VERSION "Proposition POC une paire avant - non validee pour le bus TRAXX"

NS_ :

BS_:

BU_: TRAXX_PALPEUR TRAXX_PC

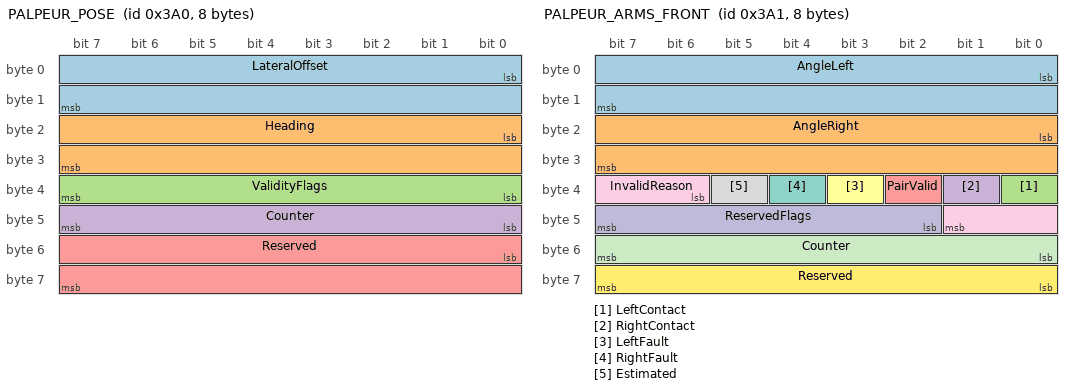
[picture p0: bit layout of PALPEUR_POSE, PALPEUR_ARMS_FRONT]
BO_ 928 PALPEUR_POSE: 8 TRAXX_PALPEUR
 SG_ LateralOffset : 0|16@1- (0.1,0) [-3276.8|3276.7] "mm" TRAXX_PC
 SG_ Heading : 16|16@1- (0.01,0) [-327.68|327.67] "deg" TRAXX_PC
 SG_ ValidityFlags : 32|8@1+ (1,0) [0|255] "" TRAXX_PC
 SG_ Counter : 40|8@1+ (1,0) [0|255] "" TRAXX_PC
 SG_ Reserved : 48|16@1+ (1,0) [0|65535] "" TRAXX_PC

BO_ 929 PALPEUR_ARMS_FRONT: 8 TRAXX_PALPEUR
 SG_ AngleLeft : 0|16@1- (0.01,0) [-327.68|327.67] "deg" TRAXX_PC
 SG_ AngleRight : 16|16@1- (0.01,0) [-327.68|327.67] "deg" TRAXX_PC
 SG_ LeftContact : 32|1@1+ (1,0) [0|1] "" TRAXX_PC
 SG_ RightContact : 33|1@1+ (1,0) [0|1] "" TRAXX_PC
 SG_ PairValid : 34|1@1+ (1,0) [0|1] "" TRAXX_PC
 SG_ LeftFault : 35|1@1+ (1,0) [0|1] "" TRAXX_PC
 SG_ RightFault : 36|1@1+ (1,0) [0|1] "" TRAXX_PC
 SG_ Estimated : 37|1@1+ (1,0) [0|1] "" TRAXX_PC
 SG_ InvalidReason : 38|4@1+ (1,0) [0|15] "" TRAXX_PC
 SG_ ReservedFlags : 42|6@1+ (1,0) [0|63] "" TRAXX_PC
 SG_ Counter : 48|8@1+ (1,0) [0|255] "" TRAXX_PC
 SG_ Reserved : 56|8@1+ (1,0) [0|255] "" TRAXX_PC

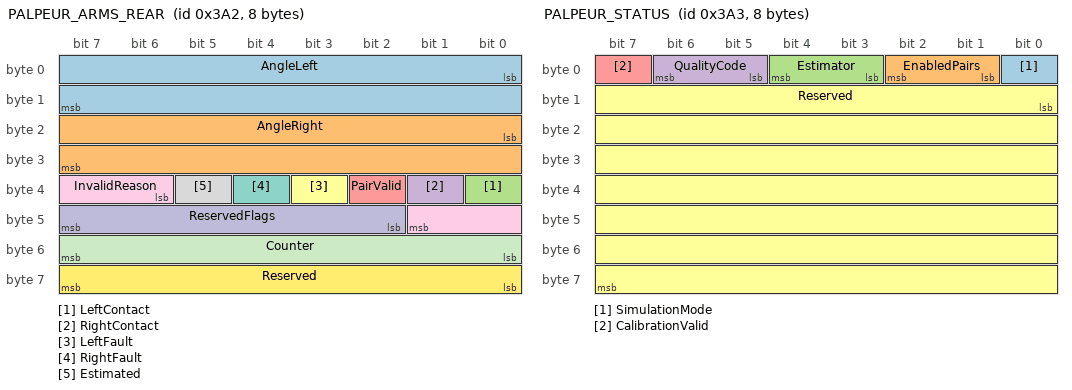
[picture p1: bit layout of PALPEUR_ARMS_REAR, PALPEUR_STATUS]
BO_ 930 PALPEUR_ARMS_REAR: 8 TRAXX_PALPEUR
 SG_ AngleLeft : 0|16@1- (0.01,0) [-327.68|327.67] "deg" TRAXX_PC
 SG_ AngleRight : 16|16@1- (0.01,0) [-327.68|327.67] "deg" TRAXX_PC
 SG_ LeftContact : 32|1@1+ (1,0) [0|1] "" TRAXX_PC
 SG_ RightContact : 33|1@1+ (1,0) [0|1] "" TRAXX_PC
 SG_ PairValid : 34|1@1+ (1,0) [0|1] "" TRAXX_PC
 SG_ LeftFault : 35|1@1+ (1,0) [0|1] "" TRAXX_PC
 SG_ RightFault : 36|1@1+ (1,0) [0|1] "" TRAXX_PC
 SG_ Estimated : 37|1@1+ (1,0) [0|1] "" TRAXX_PC
 SG_ InvalidReason : 38|4@1+ (1,0) [0|15] "" TRAXX_PC
 SG_ ReservedFlags : 42|6@1+ (1,0) [0|63] "" TRAXX_PC
 SG_ Counter : 48|8@1+ (1,0) [0|255] "" TRAXX_PC
 SG_ Reserved : 56|8@1+ (1,0) [0|255] "" TRAXX_PC

BO_ 931 PALPEUR_STATUS: 8 TRAXX_PALPEUR
 SG_ SimulationMode : 0|1@1+ (1,0) [0|1] "" TRAXX_PC
 SG_ EnabledPairs : 1|2@1+ (1,0) [0|3] "" TRAXX_PC
 SG_ Estimator : 3|2@1+ (1,0) [0|3] "" TRAXX_PC
 SG_ QualityCode : 5|2@1+ (1,0) [0|3] "" TRAXX_PC
 SG_ CalibrationValid : 7|1@1+ (1,0) [0|1] "" TRAXX_PC
 SG_ Reserved : 8|56@1+ (1,0) [0|72057594037927935] "" TRAXX_PC

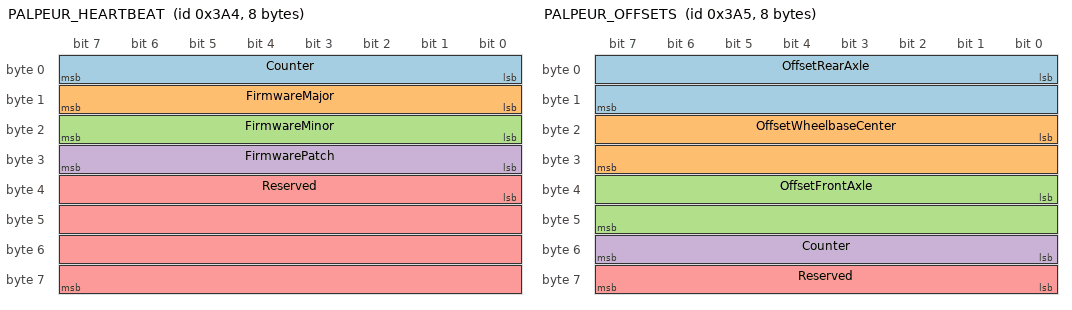
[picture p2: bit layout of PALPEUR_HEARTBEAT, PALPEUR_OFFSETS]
BO_ 932 PALPEUR_HEARTBEAT: 8 TRAXX_PALPEUR
 SG_ Counter : 0|8@1+ (1,0) [0|255] "" TRAXX_PC
 SG_ FirmwareMajor : 8|8@1+ (1,0) [0|255] "" TRAXX_PC
 SG_ FirmwareMinor : 16|8@1+ (1,0) [0|255] "" TRAXX_PC
 SG_ FirmwarePatch : 24|8@1+ (1,0) [0|255] "" TRAXX_PC
 SG_ Reserved : 32|32@1+ (1,0) [0|4294967295] "" TRAXX_PC

BO_ 933 PALPEUR_OFFSETS: 8 TRAXX_PALPEUR
 SG_ OffsetRearAxle : 0|16@1- (0.1,0) [-3276.8|3276.7] "mm" TRAXX_PC
 SG_ OffsetWheelbaseCenter : 16|16@1- (0.1,0) [-3276.8|3276.7] "mm" TRAXX_PC
 SG_ OffsetFrontAxle : 32|16@1- (0.1,0) [-3276.8|3276.7] "mm" TRAXX_PC
 SG_ Counter : 48|8@1+ (1,0) [0|255] "" TRAXX_PC
 SG_ Reserved : 56|8@1+ (1,0) [0|255] "" TRAXX_PC

VAL_ 928 ValidityFlags 0 "Invalid";
VAL_ 931 SimulationMode 0 "Real" 1 "Simulation";
VAL_ 931 Estimator 0 "None" 1 "V1" 2 "V2" 3 "Reserved";
VAL_ 931 QualityCode 0 "Invalid" 1 "Degraded" 2 "Valid" 3 "Reserved";

CM_ BO_ 928 "Proposed standard-ID frame. Offset sign is positive when the machine is left of the row. ID allocation is unverified.";
CM_ BO_ 929 "Proposed front-pair data. Angles are filtered. ID allocation is unverified.";
CM_ BO_ 930 "Reserved for a possible future rear pair; not used in the one-pair POC. ID allocation is unverified.";
CM_ BO_ 931 "Proposed status data. Quality is categorical, not a numeric confidence.";
CM_ BO_ 932 "Proposed heartbeat. ID allocation is unverified.";
CM_ BO_ 933 "Reserved for a possible future two-pair configuration to provide three lateral references.";
